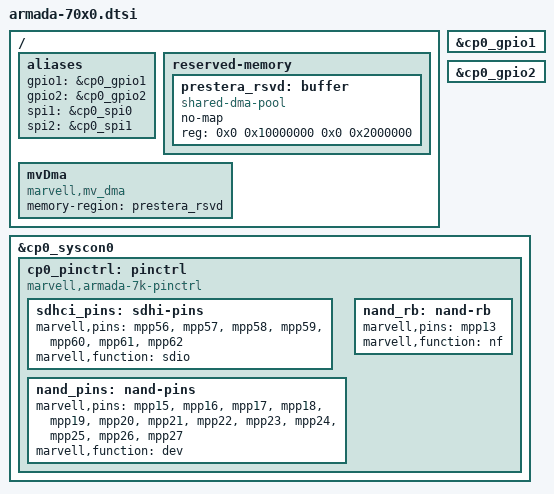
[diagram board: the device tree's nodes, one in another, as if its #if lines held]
// SPDX-License-Identifier: (GPL-2.0+ OR MIT)
/*
 * Copyright (C) 2017 Marvell Technology Group Ltd.
 *
 * Device Tree file for the Armada 70x0 SoC
 */

/*
 * Instantiate the CP110
 */
#define CP110_NUM				0
#define CP110_BASE				0xf2000000
#define CP110_PCIE_MEM_SIZE(iface)		0xf00000
#define CP110_PCIEx_CPU_MEM_BASE(iface)		(0xf6000000 + (iface) *  0x1000000)
#define CP110_PCIEx_BUS_MEM_BASE(iface)		(CP110_PCIEx_CPU_MEM_BASE(iface))
#define CP110_PCIE_BUS_MEM_CFG			(0x82000000)

#include "armada-cp110.dtsi"

#undef CP110_NUM
#undef CP110_BASE
#undef CP110_PCIE_MEM_SIZE
#undef CP110_PCIEx_CPU_MEM_BASE
#undef CP110_PCIEx_BUS_MEM_BASE
#undef CP110_PCIE_BUS_MEM_CFG

/ {
	aliases {
		gpio1 = &cp0_gpio1;
		gpio2 = &cp0_gpio2;
		spi1 = &cp0_spi0;
		spi2 = &cp0_spi1;
	};

/*  Should be unmarked, when need to enlarge legacy DMA allocation */
#ifdef NONE
	reserved-memory {
		#address-cells = <2>;
		#size-cells = <2>;
		ranges;

		prestera_rsvd: buffer {
			/* to be used as a shared pool of DMA buffers for a set of devices */
			compatible = "shared-dma-pool";
			/* No one other than devices registered for that mem, may use this area */
			no-map;

			/* Base addr (first 2 cells) requires alignment, we choose 0x10000000 */
			reg = <0x0 0x10000000 0x0 0x2000000>;
		};
	};

	mvDma {
		compatible = "marvell,mv_dma";
		memory-region = <&prestera_rsvd>;
		status = "okay";
	};
#endif

};



&cp0_gpio1 {
	status = "okay";
};

&cp0_gpio2 {
	status = "okay";
};

&cp0_syscon0 {
	cp0_pinctrl: pinctrl {
		compatible = "marvell,armada-7k-pinctrl";

		sdhci_pins: sdhi-pins {
			marvell,pins = "mpp56", "mpp57", "mpp58",
				       "mpp59", "mpp60", "mpp61", "mpp62";
			marvell,function = "sdio";
		};

		nand_pins: nand-pins {
			marvell,pins =
			"mpp15", "mpp16", "mpp17", "mpp18",
			"mpp19", "mpp20", "mpp21", "mpp22",
			"mpp23", "mpp24", "mpp25", "mpp26",
			"mpp27";
			marvell,function = "dev";
		};

		nand_rb: nand-rb {
			marvell,pins = "mpp13";
			marvell,function = "nf";
		};
	};
};
